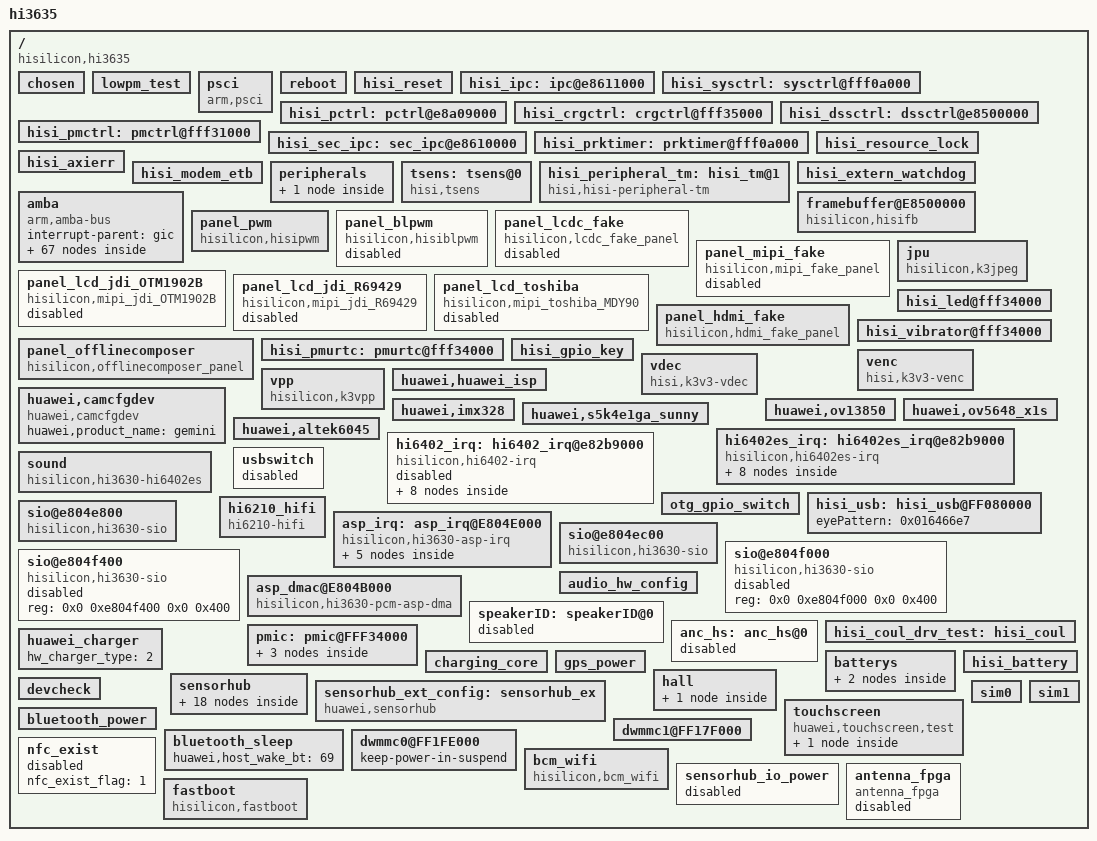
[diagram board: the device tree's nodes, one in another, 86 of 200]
/**
 * Huawei Ltd.
 * PhosphorV660
 */


/include/ "GEMINI_703L_01_pin.dtsi"
/include/ "hisi_3635.dtsi"
///include/ "GEMINI_703L_01_charger.dtsi"
///include/ "GEMINI_703L_01_pmic.dtsi"
///include/ "GEMINI_703L_01_gpio_logic.dtsi"
/include/ "hi3635_mmc.dtsi"
/include/ "hi3635_camera3.dtsi"
/include/ "hi3635_ipc.dtsi"
/include/ "hi3635_ddr.dtsi"
/include/ "hisi_6402es_codec.dtsi"
/include/ "hisi_6402_codec.dtsi"
/include/ "GEMINI_703L_01_hi6402_pin.dtsi"

/include/ "hi3635_usb.dtsi"
/include/ "hi3635_efuse.dtsi"
/include/ "huawei_usbswitch.dtsi"
/include/ "huawei_usb_gpioswitch.dtsi"

/include/ "hi3635_gpu.dtsi"
/include/ "hi3635_noc.dtsi"
/include/ "hi3635_jpeg.dtsi"
/include/ "hi3635_ion.dtsi"
/include/ "hi3635_pmu.dtsi"
/include/ "hi3635_venc.dtsi"
/include/ "hi3635_vdec.dtsi"
/include/ "hi3635_vpp.dtsi"
/include/ "hisi_sim_hotplug.dtsi"
/include/ "huawei_wifi.dtsi"
/include/ "huawei_bluetooth.dtsi"
/include/ "huawei_gps.dtsi"
/include/ "huawei-sensor.dtsi"
/include/ "bq_bci_battery.dtsi"
/include/ "huawei_charger.dtsi"
/include/ "hisi_battery.dtsi"
/include/ "batterys.dtsi"
/include/ "hisi_coul_drv_test.dtsi"
/include/ "GEMINI_703L_01_modem_pin.dtsi"
/*/include/ "huawei_touchscreen.dtsi"*/
/include/ "huawei_hall_inputhub.dtsi"
/include/ "huawei_devdetect.dtsi"
/include/ "huawei_nfc.dtsi"
/include/ "huawei_smartpa.dtsi"
/include/ "huawei_audio.dtsi"
/include/ "huawei_antenna_fpga.dtsi"
/include/ "huawei_bastet.dtsi"
/ {
	#address-cells = <2>;
	#size-cells = <2>;
	model = "hi3635";
	compatible = "hisilicon,hi3635";
	interrupt-parent = <&gic>;

	hisi,boardid = <1 1 0 0 >;
	hisi,boardname = "GEMINI_703L_01";
	hisi,modem_id = <0x3EF50880>;
	hisi,hardware_version="STENGEM703LAPV0001";
	chosen{};

	lowpm_test {
		status = "ok";
	};

	psci {
		compatible      = "arm,psci";
		method          = "smc";
		cpu_suspend     = <0xc4000001>;
		cpu_off         = <0x84000002>;
		cpu_on          = <0xc4000003>;
		system_off      = <0x84000008>;
		system_reset    = <0x84000009>;
	};

	reboot {
		status = "ok";
	};

	hisi_reset {
		status = "ok";
	};

	hisi_ipc: ipc@e8611000 {
		status = "ok";
	};

	hisi_sysctrl: sysctrl@fff0a000 {
		status = "ok";
	};

	hisi_pctrl: pctrl@e8a09000 {
		status = "ok";
	};

	hisi_crgctrl: crgctrl@fff35000 {
		status = "ok";
	};

	hisi_dssctrl: dssctrl@e8500000 {
		status = "ok";
	};

	hisi_pmctrl: pmctrl@fff31000 {
		status = "ok";
	};

	hisi_sec_ipc: sec_ipc@e8610000 {
		status = "ok";
	};

	hisi_prktimer: prktimer@fff0a000 {
		status = "ok";
	};

	hisi_resource_lock {
		status = "ok";
	};

	hisi_axierr {
		status = "ok";
	};

	hisi_modem_etb {
		status = "ok";
	};

	peripherals {
		dma0: dma@fdf30000 {
			status = "ok";
		};
	};

	tsens: tsens@0{
		compatible = "hisi,tsens";
		hisi,sensors = <5>;
		hisi,tsensor_enable_cmd = <0x000E000B>;
		hisi,tsensor_disable_cmd = <0x000E010B>;
		hisi,tsensor_read_thermal_h_cmd = <0x000E0208>;
		hisi,tsensor_read_thermal_l_cmd = <0x000E0209>;
		hisi,tsensor_write_thermal_h_cmd = <0x000E0308>;
		hisi,tsensor_write_thermal_l_cmd = <0x000E0309>;
		hisi,tsensor_read_temperature_cmd = <0x000E020B>;
		hisi,tsensor_int_reback_cmd = <0x080E030B>;
	};

	hisi_peripheral_tm: hisi_tm@1 {
		compatible = "hisi,hisi-peripheral-tm";
		hisi,peripheral_sensors = <13>;

		hisi,detect_system_h_tm_chanel = <3>;
		hisi,detect_system_h_tm_ntc = "hi3630_volt_to_temp_general1";
		hisi,detect_system_h_tm_state = "enable";

		hisi,detect_sim_tm_chanel = <5>;
		hisi,detect_sim_tm_ntc = "hi3630_volt_to_temp_general1";
		hisi,detect_sim_tm_state = "disable";

		hisi,detect_system_l_tm_chanel = <6>;
		hisi,detect_system_l_tm_ntc = "hi3630_volt_to_temp_general1";
		hisi,detect_system_l_tm_state = "enable";

		hisi,detect_flash_led_tm_chanel = <9>;
		hisi,detect_flash_led_tm_ntc = "hi3630_volt_to_temp_general1";
		hisi,detect_flash_led_tm_state = "enable";

		hisi,detect_charger_tm_chanel = <12>;
		hisi,detect_charger_tm_ntc = "hi3630_volt_to_temp_general1";
		hisi,detect_charger_tm_state = "enable";

		hisi,detect_pa_0_tm_chanel = <11>;
		hisi,detect_pa_0_tm_ntc = "hi3630_volt_to_temp_general1";
		hisi,detect_pa_0_tm_state = "enable";

		hisi,detect_pa_1_tm_chanel = <13>;
		hisi,detect_pa_1_tm_ntc = "hi3630_volt_to_temp_general1";
		hisi,detect_pa_1_tm_state = "disable";

		hisi,detect_dcxo0_tm_chanel = <10>;
		hisi,detect_dcxo0_tm_ntc = "hi3630_volt_to_temp_general1";
		hisi,detect_dcxo0_tm_state = "disable";

		hisi,detect_dcxo1_tm_chanel = <12>;
		hisi,detect_dcxo1_tm_ntc = "hi3630_volt_to_temp_general1";
		hisi,detect_dcxo1_tm_state = "disable";

		hisi,detect_board0_tm_chanel = <14>;
		hisi,detect_board0_tm_ntc = "hi3630_volt_to_temp_general1";
		hisi,detect_board0_tm_state = "disable";

		hisi,detect_board1_tm_chanel = <15>;
		hisi,detect_board1_tm_ntc = "hi3630_volt_to_temp_general1";
		hisi,detect_board1_tm_state = "disable";

		hisi,detect_board2_tm_chanel = <16>;
		hisi,detect_board2_tm_ntc = "hi3630_volt_to_temp_general1";
		hisi,detect_board2_tm_state = "disable";

		hisi,detect_board3_tm_chanel = <17>;
		hisi,detect_board3_tm_ntc = "hi3630_volt_to_temp_general1";
		hisi,detect_board3_tm_state = "disable";
	};

	hisi_extern_watchdog {
		status = "ok";
	};

	amba {
		#address-cells = <1>;
		#size-cells = <1>;
		compatible = "arm,amba-bus";
		interrupt-parent = <&gic>;
		ranges;

		rtc@FFF04000 {
			status = "ok";
		};

		wdt0@e8a06000 {
			status = "ok";
		};

		serial0: uart@fdf02000 {
			status = "ok";
		};

		serial1: uart@fdf00000 {
			status = "ok";
		};

		serial2: uart@fdf03000 {
			status = "ok";

		};

		serial3: uart@fdf04000 {
			status = "ok";
		};

		serial4: uart@fdf01000 {
			status = "ok";
		};

		serial5: uart@fdf05000 {
			status = "ok";
		};

		serial6: uart@fff32000 {
			status = "ok";
		};

		hisi_timer4: timer4@e8a00000 {
			status = "ok";
		};

		gpio0: gpio@e8a0b000 {
			status = "ok";
		};

		gpio1: gpio@e8a0c000 {
			status = "ok";
		};

		gpio2: gpio@e8a0d000 {
			status = "ok";
		};

		gpio3: gpio@e8a0e000 {
			status = "ok";
		};

		gpio4: gpio@e8a0f000 {
			status = "ok";
		};

		gpio5: gpio@e8a10000 {
			status = "ok";
		};

		gpio6: gpio@e8a11000 {
			status = "ok";
		};

		gpio7: gpio@e8a12000 {
			status = "ok";
		};

		gpio8: gpio@e8a13000 {
			status = "ok";
		};

		gpio9: gpio@e8a14000 {
			status = "ok";
		};

		gpio10: gpio@e8a15000 {
			status = "ok";
		};

		gpio11: gpio@e8a16000 {
			status = "ok";
		};

		gpio12: gpio@e8a17000 {
			status = "ok";
		};

		gpio13: gpio@e8a18000 {
			status = "ok";
		};

		gpio14: gpio@e8a19000 {
			status = "ok";
		};

		gpio15: gpio@e8a1a000 {
			status = "ok";
		};

		gpio16: gpio@e8a1b000 {
			status = "ok";
		};

		gpio17: gpio@e8a1c000 {
			status = "ok";
		};

		gpio18: gpio@e8a1d000 {
			status = "ok";
		};

		gpio19: gpio@e8a1e000 {
			status = "ok";
		};

		gpio20: gpio@e8a1f000 {
			status = "ok";
		};

		gpio21: gpio@e8a20000 {
			status = "ok";
		};

		gpio22: gpio@fff0b000 {
			status = "ok";
		};

		gpio23: gpio@fff0c000 {
			status = "ok";
		};

		gpio24: gpio@fff0d000 {
			status = "ok";
		};

		gpio25: gpio@fff0e000 {
			status = "ok";
		};

		gpio26: gpio@fff0f000 {
			status = "ok";
		};

		spi0: spi@fdf07000 {
			status = "ok";
			num-cs = <5>;
			pinctrl-names = "default", "idle";
			pinctrl-0 = <&gpio063_pmx_func &gpio065_pmx_func &gpio066_pmx_func &gpio067_pmx_func
					 &gpio068_pmx_func &gpio069_pmx_func &gpio063_cfg_func &gpio064_cfg_func
					 &gpio065_cfg_func &gpio066_cfg_func &gpio068_cfg_func
					 &gpio069_cfg_func>;
			pinctrl-1 = <&gpio063_pmx_idle &gpio065_pmx_idle &gpio066_pmx_idle &gpio067_pmx_idle
					 &gpio068_pmx_idle &gpio069_pmx_idle &gpio063_cfg_idle &gpio064_cfg_idle
					 &gpio065_cfg_idle &gpio066_cfg_idle &gpio068_cfg_idle
					 &gpio069_cfg_idle>;
			#address-cells = <1>;
			#size-cells = <0>;
			//cs-gpios = <&gpio9 7 0>, <&gpio10 0 0>, <&gpio10 1 0>, <&gpio10 2 0>;

			mini_isp: mini_isp@0 {
				compatible = "mini_isp";
				spi-max-frequency = <26000000>;
				reg = <0>;
				pl022,com-mode = <2>;
				pl022,interface = <0>;
				pl022,rx-level-trig = <3>;
				pl022,tx-level-trig = <3>;
				pl022,ctrl-len = <7>;
				pl022,wait-state = <0>;
				pl022,duplex = <0>;
				pl022,slave-tx-disable = <0>;

				mini_isp,reset_gpio = <23>;
				mini_isp,cs_gpio = <66>;
				mini_isp,irq_gpio = <24>;
				mini_isp,dvdd_gpio = <22>;
				mini_isp,vcc_gpio = <210>;
				iopw-supply = <&lsw51>;
				pinctrl-names = "default", "idle";
				pinctrl-0 = <&gpio023_pmx_func &gpio023_cfg_func>;
				pinctrl-1 = <&gpio023_pmx_idle &gpio023_cfg_idle>;
			};

			spi_dev1: spi_dev1@1 {
				compatible = "spi_dev1";
				spi-max-frequency = <100000>;
				reg = <1>;
				pl022,com-mode = <0>;
				pl022,interface = <0>;
				pl022,rx-level-trig = <3>;
				pl022,tx-level-trig = <3>;
				pl022,ctrl-len = <7>;
				pl022,wait-state = <0>;
				pl022,duplex = <0>;
				pl022,slave-tx-disable = <0>;
			};

			spi_dev2: spi_dev2@2 {
				compatible = "spi_dev2";
				spi-max-frequency = <100000>;
				reg = <2>;
				pl022,com-mode = <0>;
				pl022,interface = <0>;
				pl022,rx-level-trig = <3>;
				pl022,tx-level-trig = <3>;
				pl022,ctrl-len = <7>;
				pl022,wait-state = <0>;
				pl022,duplex = <0>;
				pl022,slave-tx-disable = <0>;
			};

			spi_dev3: spi_dev3@3 {
				compatible = "spi_dev3";
				spi-max-frequency = <100000>;
				reg = <3>;
				pl022,com-mode = <0>;
				pl022,interface = <0>;
				pl022,rx-level-trig = <3>;
				pl022,tx-level-trig = <3>;
				pl022,ctrl-len = <7>;
				pl022,wait-state = <0>;
				pl022,duplex = <0>;
				pl022,slave-tx-disable = <0>;
			};
			fpga_spi: fpga_spi@4 {
				compatible = "fpga_spi";
				spi-max-frequency = <0x989680>;
				reg = <4>;
				pl022,com-mode = <2>;
				pl022,interface = <0>;
				pl022,rx-level-trig = <3>;
				pl022,tx-level-trig = <3>;
				pl022,ctrl-len = <7>;
				pl022,wait-state = <0>;
				pl022,duplex = <0>;
				pl022,slave-tx-disable = <0>;
			};
		};

		spi1: spi@fdf08000 {
			status = "ok";
			num-cs = <1>;
			pinctrl-names = "default", "idle";
			pinctrl-0 = <>;
			pinctrl-1 = <>;
			/*
			pinctrl-0 = <&gpio146_pmx_func &gpio147_pmx_func &gpio148_pmx_func &gpio149_pmx_func
				     &gpio146_cfg_func &gpio147_cfg_func &gpio148_cfg_func &gpio149_cfg_func>;
			pinctrl-1 = <&gpio146_pmx_idle &gpio147_pmx_idle &gpio148_pmx_idle &gpio149_pmx_idle
				     &gpio146_cfg_idle &gpio147_cfg_idle &gpio148_cfg_idle &gpio149_cfg_idle>;
			*/
			#address-cells = <1>;
			#size-cells = <0>;
			/*
			spi_dev4: spi_dev4@4 {
				compatible = "spi_dev4";
				spi-max-frequency = <100000>;
				reg = <4>;
				pl022,com-mode = <1>;
				pl022,interface = <0>;
				pl022,rx-level-trig = <3>;
				pl022,tx-level-trig = <3>;
				pl022,ctrl-len = <7>;
				pl022,wait-state = <0>;
				pl022,duplex = <0>;
				pl022,slave-tx-disable = <0>;
			};
			*/
		};

		/* I2C0 ~ I2C4
		Notation for touchscreen and other devices, that is not defined in I2C DTS node:
		if any I2C adapter is disabled, corresponding I2C ID should decreased one by
		one, for example:
			if only I2C0 is disabled, slave devices on I2C1 should get adapter by ID 0
			if only I2C1 is disabled, slave devices on I2C2 should get adapter by ID 1
			and so on........
		*/
		i2c0: i2c@FDF09000 {
			status = "disabled";
			pinctrl-names = "default", "idle";
			pinctrl-0 = <&gpio047_pmx_func &gpio047_cfg_func &gpio048_cfg_func>;
			pinctrl-1 = <&gpio047_pmx_idle &gpio047_cfg_idle &gpio048_cfg_idle>;
			cs-gpios = <&gpio5 7 0>, <&gpio6 0 0>;
		};

		i2c1: i2c@FDF0A000 {
			status = "ok";
			pinctrl-names = "default", "idle";
			pinctrl-0 = <&gpio049_pmx_func &gpio049_cfg_func &gpio050_cfg_func>;
			pinctrl-1 = <&gpio049_pmx_idle &gpio049_cfg_idle &gpio050_cfg_idle>;
			cs-gpios = <&gpio6 1 0>, <&gpio6 2 0>;

			huawei,lm3642@63{
				huawei,flash_current = <0x9>;
				huawei,torch_current = <0x3>;
				status = "ok";
			};

			tps65132_phy: tps65132@3e {
			    compatible = "hisilicon,tps65132_phy";
			    reg = <0x3e>;
			    gpios = <&gpio5 1 0>, <&gpio5 2 0>;
			    status = "ok";
			};
			fairchild_fsa9685: fsa9685@25 {
				 status = "disabled";
			};
			bq2419x_charger:charger@6B {
				status = "disable";
			};
			bq2429x_charger:bq2429x_charger@6B {
				status = "ok";
			};
			max98925_smartpa:smartpa@31{
				status = "ok";
			};
			pn547_nfc:nfc@28 {
				status = "disabled";
				nfc_nxp_name = "libnfc-nxp.conf";
			};
		};

		i2c2: i2c@FDF0B000 {
			status = "ok";
			pinctrl-names = "default", "idle";
			pinctrl-0 = <&gpio051_pmx_func &gpio051_cfg_func &gpio052_cfg_func>;
			pinctrl-1 = <&gpio051_pmx_idle &gpio051_cfg_idle &gpio052_cfg_idle>;
			cs-gpios = <&gpio6 3 0>, <&gpio6 4 0>;

                        cypress_touchscreen@24 {
                               compatible = "cy,cyttsp5_i2c_adapter";
                               reg = <0x24>;
                               cy,adapter_id = "cyttsp5_i2c_adapter";

			       vci_power_type   = <0>; /*0 - gpio control  1 - LDO  2 - boost & gpio*/
                               cypress_vci-supply;
			       vci_gpio_enable  = <&gpio9 1 0>;
			       vci_boost_enable;

			       vddio_power_type   = <1>; /*0 - gpio control  1 - LDO*/
                               cypress_vddio-supply = <&lsw50>;
			       vddio_gpio_enable;
                               
			       cy,i2c_read_length = <100>;
			       pinctrl-names = "default", "idle";
		               pinctrl-0 = <&gpio200_pmx_func  &gpio200_cfg_func>;
                               pinctrl-1 = <&gpio200_pmx_idle  &gpio200_cfg_idle>; 

				hw,mmi_test_limit =
					"0","255","6","0","255","6","0","255","6","0","255","6",                     /*mmi_idac_limit*/
					"79","120","79","120","79","120","75","120",                                 /*mmi_localPWC_limit*/
					"25","4","8", "21","16","10","200","25","5","9", "21","16","10","200",       /*mmi_opens_limit*/
					"25","4","10","21","16","10","200","25","6","10","21","16","10","200",       /*mmi_opens_limit*/
					"-2000","2000","0","-2000","2000","0","-2000","2000","0","-2000","2000","0", /*mmi_mut_rawdata_limit*/
					"-7500","7500","0","-7500","7500","0","-7500","7500","0","-7500","7500","0", /*mmi_self_rawdata_limit*/
					"10","35","255","0","27","10","35","255","0","27",                           /*mmi_selflocalPWC_limit*/
					"10","35","255","0","27","10","35","255","0","30";                           /*mmi_selflocalPWC_limit*/

                               cy,core {
                                       cy,id = "main_ttsp_core";
                                       cy,name = "cyttsp5_core";
                                       cy,irq_gpio = <&gpio25 0 0>;
                                       cy,rst_gpio = <&gpio12 2 0>;
                                       cy,hid_desc_register = <1>;
				       cy,product_name = "Gemini";
				       cy,support_chip_name = "TMA568";
                                       cy,flags = <0>;/*CY_CORE_FLAG_WAKE_ON_GESTURE | CY_CORE_FLAG_RESTORE_PARAMETERS*/
                                       cy,easy_wakeup_gesture = <0>;
                                       cy,upgrade_ttconfig = <0>;
                                       cy,has_touchplus = <1>;
                                       cy,has_holster = <1>;
                                       cy,no_cali_flag = <1>;

			               cy,btn_keys =
                                       <189   /* TS_TOUCHPLUS_KEY0 = KEY_F21, //189 */
				        190   /* TS_TOUCHPLUS_KEY1 = KEY_F22, //190 */
				        191   /* TS_TOUCHPLUS_KEY2 = KEY_F23, //191 */
				        192   /* TS_TOUCHPLUS_KEY3 = KEY_F19, //192 */
				        193>; /* TS_TOUCHPLUS_KEY4 = KEY_F20, //193 */
                                       cy,btn_keys-tag = <0>;
                               cy,mt   {
                                       cy,name = "cyttsp5_mt";
                                       cy,inp_dev_name = "cyttsp5_mt";
                                       cy,flags = <0x00>;/* CY_MT_FLAG_FLIP | CY_MT_FLAG_INV_X | CY_MT_FLAG_INV_Y */
                                       cy,abs =
                                       <0x35   0 1200 0 0           /* ABS_MT_POSITION_X, CY_ABS_MIN_X, CY_ABS_MAX_X, 0, 0 */
                                        0x36   0 1920 0 0           /* ABS_MT_POSITION_Y, CY_ABS_MIN_Y, CY_ABS_MAX_Y, 0, 0 */
                                        0x3a   0 255  0 0           /* ABS_MT_PRESSURE,   CY_ABS_MIN_P, CY_ABS_MAX_P, 0, 0 */
                                        0xffff 0 255  0 0           /* CY_IGNORE_VALUE,   CY_ABS_MIN_W, CY_ABS_MAX_W, 0, 0 */
                                        0x39   0 15   0 0           /* ABS_MT_TRACKING_ID,CY_ABS_MIN_T, CY_ABS_MAX_T, 0, 0 */
                                        0x30   0 255  0 0           /* ABS_MT_TOUCH_MAJOR,0, 255, 0, 0 */
                                        0x31   0 255  0 0           /* ABS_MT_TOUCH_MINOR,0, 255, 0, 0 */
                                        0x34   0xfffffed7 127 0 0>; /* ABS_MT_ORIENTATION,-128, 127, 0, 0 */
                                       };
			       cy,btn {
			              cy,name = "cyttsp5_btn";
				      cy,inp_dev_name = "cyttsp5_btn";
			              };
                               };
                       };   
		};

		i2c3: i2c@FDF0C000 {
			status = "ok";
			pinctrl-names = "default", "idle";
			pinctrl-0 = <&gpio017_pmx_func &gpio018_pmx_func &gpio017_cfg_func &gpio018_cfg_func>;
			pinctrl-1 = <&gpio017_pmx_idle &gpio018_pmx_idle &gpio017_cfg_idle &gpio018_cfg_idle>;
			cs-gpios = <&gpio2 1 0>, <&gpio2 2 0>;

			big-core-mon@40 {
				compatible = "hisilicon,big-core-mon";
				reg = <0x40>;
				status = "ok";
			};
			little-core-mon@41 {
				compatible = "hisilicon,little-core-mon";
				reg = <0x41>;
				status = "ok";
			};
			gpu-mon@42 {
				compatible = "hisilicon,gpu-mon";
				reg = <0x42>;
				status = "ok";
			};
			ddr-mon@44 {
				compatible = "hisilicon,ddr-mon";
				reg = <0x44>;
				status = "ok";
			};
			peri-mon@45 {
				compatible = "hisilicon,peri-mon";
				reg = <0x45>;
				status = "ok";
			};
			battery-mon@46 {
				compatible = "hisilicon,battery-mon";
				reg = <0x46>;
				status = "ok";
			};
		};

		i2c4: i2c@FDF0D000 {
			status = "ok";
			pinctrl-names = "default", "idle";
			pinctrl-0 = <&gpio053_pmx_func &gpio053_cfg_func &gpio054_cfg_func>;
			pinctrl-1 = <&gpio053_pmx_idle &gpio053_cfg_idle &gpio054_cfg_idle>;
			cs-gpios = <&gpio6 5 0>, <&gpio6 6 0>;
		};

		hifidsp {
			compatible = "hisilicon,k3hifidsp";
			reg = <0x0 0xE804E000 0x0 0x120>;
			status = "ok";
		};
	};
	/* end amba */

	/* framebuffer & panel begin */
	framebuffer@E8500000 {
		#address-cells = <2>;
		#size-cells = <2>;
		compatible = "hisilicon,hisifb";
		fpga_flag = <0>;
		fastboot_enable_flag = <0>;
		// dss base, CRGPERI base
		reg = <0 0xE8500000 0 0x80000>, <0 0xFFF35000 0 0x1000>;
		// dss-pdp, dss-sdp, dss-adp, dss-dsi0, dss-dsi1 irq
		interrupts = <0 145 4>, <0 146 4>, <0 147 4>, <0 151 4>, <0 152 4>;
		regulator_dsssubsys-supply = <&dsssubsys>;
		regulator_sdp-supply = <&sdp>;
		regulator_adp-supply = <&adp>;
		clocks = <&aclk_gate_dss>, <&clk_gate_edc0>, <&clk_gate_edc1>, <&clk_gate_ldi0>, <&clk_gate_ldi1>, <&pclk_gate_dss>, <&clk_gate_dphy0>, <&clk_gate_dphy1>;
		clock-names = "aclk_dss", "clk_edc0", "clk_edc1", "clk_ldi0", "clk_ldi1", "pclk_dss", "clk_dphy0", "clk_dphy1";
		status = "ok";
	};

	panel_pwm {
		#address-cells = <2>;
		#size-cells = <2>;
		compatible = "hisilicon,hisipwm";
		reg = <0 0xE8A04000 0 0x1000>;
		clocks = <&clk_gate_pwm>;
		clock-names = "clk_pwm";
		pinctrl-names = "default","idle";
		pinctrl-0 = <&gpio098_pmx_func &gpio098_cfg_func>;
		pinctrl-1 = <&gpio098_pmx_idle &gpio098_cfg_idle>;
		status = "ok";
	};

	panel_blpwm {
		#address-cells = <2>;
		#size-cells = <2>;
		compatible = "hisilicon,hisiblpwm";
		reg = <0 0xE8A05000 0 0x1000>;
		clocks = <&clk_gate_pwm1>;
		clock-names = "clk_pwm1";
		pinctrl-names = "default","idle";
		pinctrl-0 = <&gpio098_pmx_func &gpio098_cfg_func>;
		pinctrl-1 = <&gpio098_pmx_idle &gpio098_cfg_idle>;
		status = "disabled";
	};

	panel_lcdc_fake {
		#address-cells = <2>;
		#size-cells = <2>;
		compatible = "hisilicon,lcdc_fake_panel";
		status = "disabled";
	};

	panel_mipi_fake {
		#address-cells = <2>;
		#size-cells = <2>;
		compatible = "hisilicon,mipi_fake_panel";
		gpios = <&gpio4 3 0>, <&gpio4 5 0>, <&gpio4 6 0>, <&gpio5 1 0>, <&gpio5 2 0>, <&gpio2 3 0>;
		lcdio-vcc-supply = <&lsw50>;
		lcdanalog-vcc-supply = <&ldo17>;
		lcd-vddio-type = <1>;
		status = "disabled";
	};

	panel_lcd_jdi_OTM1902B {
		#address-cells = <2>;
		#size-cells = <2>;
		compatible = "hisilicon,mipi_jdi_OTM1902B";
		gpios = <&gpio4 3 0>, <&gpio4 5 0>, <&gpio4 6 0>, <&gpio5 1 0>, <&gpio5 2 0>;
		lcdio-vcc-supply = <&lsw50>;
		lcdanalog-vcc-supply = <&ldo17>;
		lcd-bl-type = <8>;
		lcd-vddio-type = <1>;
		pinctrl-names = "default", "idle";
		pinctrl-0 = <&gpio036_pmx_func &gpio035_cfg_func &gpio036_cfg_func &gpio037_cfg_func &gpio038_cfg_func &gpio041_cfg_func &gpio042_cfg_func>;
		pinctrl-1 = <&gpio036_pmx_idle &gpio035_cfg_idle &gpio036_cfg_idle &gpio037_cfg_idle &gpio038_cfg_idle &gpio041_cfg_idle &gpio042_cfg_idle>;
		status = "disabled";
	};


	panel_lcd_jdi_R69429 {
		#address-cells = <2>;
		#size-cells = <2>;
		compatible = "hisilicon,mipi_jdi_R69429";
		gpios = <&gpio4 3 0>, <&gpio4 5 0>, <&gpio4 6 0>, <&gpio5 1 0>, <&gpio5 2 0>;		
		lcd-bl-type = <8>;
		lcd-vddio-type = <1>;
		pinctrl-names = "default", "idle";
		pinctrl-0 = <&gpio036_pmx_func &gpio035_cfg_func &gpio036_cfg_func &gpio037_cfg_func &gpio038_cfg_func &gpio041_cfg_func &gpio042_cfg_func>;
		pinctrl-1 = <&gpio036_pmx_idle &gpio035_cfg_idle &gpio036_cfg_idle &gpio037_cfg_idle &gpio038_cfg_idle &gpio041_cfg_idle &gpio042_cfg_idle>;
		status = "disabled";
	};

	panel_lcd_toshiba {
		#address-cells = <2>;
		#size-cells = <2>;
		compatible = "hisilicon,mipi_toshiba_MDY90";
		gpios = <&gpio4 5 0>, <&gpio5 1 0>;
		lcdio-vcc-supply = <&lsw50>;
		lcdanalog-vcc-supply = <&ldo17>;
		pinctrl-names = "default", "idle";
		pinctrl-0 = <&gpio037_cfg_func &gpio041_cfg_func>;
		pinctrl-1 = <&gpio037_cfg_idle &gpio041_cfg_idle>;
		status = "disabled";
	};

	panel_hdmi_fake {
		#address-cells = <2>;
		#size-cells = <2>;
		compatible = "hisilicon,hdmi_fake_panel";
		status = "ok";
	};

	panel_offlinecomposer {
		#address-cells = <2>;
		#size-cells = <2>;
		compatible = "hisilicon,offlinecomposer_panel";
		status = "ok";
	};
	/* framebuffer & panel end */

	jpu{
		compatible = "hisilicon,k3jpeg";
		reg = <0x0 0xE8960000 0x0 0x7FFF>;
		interrupts = <0 140 4>;
		//clock
		clocks = <&clk_gate_jpeg>;
		clock-names = "clk_jpeg";
		//these are for ldo resources
		ldo_jpu-supply = <&jpegip>;
		status = "ok";
	};

	hisi_pmurtc: pmurtc@fff34000 {
		status = "ok";
	};

	hisi_led@fff34000 {
		hi6421,dr3ctrl = "red";
		hi6421,dr4ctrl = "green";
		status = "ok";
	};
	hisi_vibrator@fff34000 {
		/* 1 vibrator working LRA,0 working ERM*/
		hisi,erm_lra = <0>;
		/* 0:2.7V  1:2.8V 2:3.0V 3:3.3V */
		hisi,dr2_test = <2>;
		status = "ok";
	};

	hisi_gpio_key {
		status = "ok";
	};

	venc{
		compatible = "hisi,k3v3-venc";
		reg = <0x0 0xe8900000 0x0 0x10000>;
		interrupts = <0 143 4>;
		clocks = <&clk_gate_venc>;
		clock-names = "clk_venc";
		ldo_venc-supply = <&venc>;
		status = "ok";
	};

	vdec{
		compatible = "hisi,k3v3-vdec";
		reg = <0x0 0xe8910000 0x0 0x10000>;
		interrupts = <0 144 4>;
		clocks = <&clk_gate_vdec>;
		clock-names = "clk_vdec";
		ldo_vdec-supply = <&vdec>;
		status = "ok";
	};

	vpp{
		compatible = "hisilicon,k3vpp";
		reg = <0x0 0xE8968000 0x0 0x1FFF>;
		interrupts = <0 141 4>;
		//clock
		clocks = <&clk_gate_vpp>;
		clock-names = "clk_vpp";
		//these are for ldo resources
		ldo_vpp-supply = <&vppip>;
		status = "ok";
	};

	/* isp & camera sensor & vcm begin */
	/* camera subsystem device */
	huawei,huawei_isp {
		pinctrl-0 = <&gpio031_pmx_func
			     &gpio032_pmx_func
			     &gpio210_pmx_func
			     &gpio022_cfg_func
			     &gpio025_cfg_func
			     &gpio026_cfg_func
			     &gpio027_cfg_func
			     &gpio028_cfg_func
			     &gpio029_cfg_func
			     &gpio030_cfg_func
			     &gpio031_cfg_func
			     &gpio032_cfg_func
			     &gpio033_cfg_func
			     &gpio210_cfg_func
			     >;
		pinctrl-1 = <&gpio031_pmx_idle
			     &gpio032_pmx_idle
			     &gpio210_pmx_idle
			     &gpio022_cfg_idle
			     &gpio025_cfg_idle
			     &gpio026_cfg_idle
			     &gpio027_cfg_idle
			     &gpio028_cfg_idle
			     &gpio029_cfg_idle
			     &gpio030_cfg_idle
			     &gpio031_cfg_idle
			     &gpio032_cfg_idle
			     &gpio033_cfg_idle
			     &gpio210_cfg_idle
			     >;
		status = "ok";
	};

	huawei,camcfgdev {
			compatible = "huawei,camcfgdev";
			huawei,product_name = "gemini";
			status = "ok";
	};

	/* camera sensor device */
	huawei,imx328 {
		status = "ok";
	};

	huawei,ov13850{
		status = "ok";
	};

	huawei,s5k4e1ga_sunny {
		huawei,sensor_chipid = <0xf541>;

		miniisp-supply = <&lsw51>;
		huawei,ldo-names = "avdd", "iopw","miniisp";
		status = "ok";
	};

	huawei,ov5648_x1s {
		huawei,sensor_name = "ov5648";
		miniisp-supply = <&lsw51>;
		huawei,ldo-names = "avdd", "iopw","miniisp";
		status = "ok";
	};

	/* vcm device */

	/* mini isp altek6045&6010 */
	huawei,altek6045 {
		status = "ok";
	};

	/* flash device */
	/* see i2c1: i2c@FDF0A000 -----	huawei,lm3642@63 */

	/* isp & camera sensor & vcm end */

	hi6402es_irq: hi6402es_irq@e82b9000 {
		compatible = "hisilicon,hi6402es-irq";
		hi6402es-irq-supply = <&ldo8>;
		gpios = <&gpio24 6 0>; /* GPIO_198 */
		pinctrl-names = "default", "idle";
		pinctrl-0 = <&gpio016_cfg_func &gpio016_pmx_func
			     &gpio198_cfg_func>;
		pinctrl-1 = <&gpio016_cfg_idle &gpio016_pmx_idle
			     &gpio198_cfg_idle>;
		status = "ok";
		hi6402es_codec: hi6402es_codec@0{
			compatible = "hisilicon,hi6402es-codec";
			hi6402es-codec-supply = <&ldo8>;
			status = "ok";
		};

		hi6402es_mbhc: hi6402es_mbhc@0{
			compatible = "hisilicon,hi6402es-mbhc";
			hisilicon,hs_det = <0>;
			hisilicon,hs_3_pole_min_voltage = <0>;
			hisilicon,hs_3_pole_max_voltage = <8>;
			hisilicon,hs_4_pole_min_voltage = <1350>;
			hisilicon,hs_4_pole_max_voltage = <2565>;
			hisilicon,btn_play_min_voltage = <0>;
			hisilicon,btn_play_max_voltage = <100>;
			hisilicon,btn_volume_up_min_voltage = <130>;
			hisilicon,btn_volume_up_max_voltage = <320>;
			hisilicon,btn_volume_down_min_voltage = <320>;
			hisilicon,btn_volume_down_max_voltage = <700>;
			status = "ok";
		};

		hi6402es_dsp: hi6402es_dsp@0{
			compatible = "hisilicon,hi6402es-dsp";
			status = "ok";
		};

		gpioes28: gpioes@0{
			status = "ok";
		};

		gpioes29: gpioes@1{
			status = "ok";
		};

		gpioes30: gpioes@2{
			status = "ok";
		};

		gpioes31: gpioes@3{
			status = "ok";
		};

		pmxes4: hi6402es_pinctrl {
			status = "ok";
		};
	};

	hi6402_irq: hi6402_irq@e82b9000 {
		compatible = "hisilicon,hi6402-irq";
		hi6402-irq-supply = <&ldo8>;
		hi6402-irq-ldo26-supply = <&ldo26>;
		gpios = <&gpio24 6 0>; /* GPIO_198 */
		pinctrl-names = "default", "idle";
		pinctrl-0 = <&gpio016_cfg_func &gpio016_pmx_func
			     &gpio198_cfg_func>;
		pinctrl-1 = <&gpio016_cfg_idle &gpio016_pmx_idle
			     &gpio198_cfg_idle>;
		status = "disabled";
		hi6402_codec: hi6402_codec@0{
			compatible = "hisilicon,hi6402-codec";
			status = "disabled";
		};

		hi6402_mbhc: hi6402_mbhc@0{
			compatible = "hisilicon,hi6402-mbhc";
			hisilicon,hs_det = <0>;
			hisilicon,hs_3_pole_min_voltage = <0>;
			hisilicon,hs_3_pole_max_voltage = <8>;
			hisilicon,hs_4_pole_min_voltage = <1350>;
			hisilicon,hs_4_pole_max_voltage = <2565>;
			hisilicon,btn_play_min_voltage = <0>;
			hisilicon,btn_play_max_voltage = <100>;
			hisilicon,btn_volume_up_min_voltage = <130>;
			hisilicon,btn_volume_up_max_voltage = <320>;
			hisilicon,btn_volume_down_min_voltage = <320>;
			hisilicon,btn_volume_down_max_voltage = <700>;
			status = "disabled";
		};

		hi6402_dsp: hi6402_dsp@0{
			compatible = "hisilicon,hi6402-dsp";
			status = "disabled";
		};

		gpio28: gpio@0{
			status = "disabled";
		};

		gpio29: gpio@1{
			status = "disabled";
		};

		gpio30: gpio@2{
			status = "disabled";
		};

		gpio31: gpio@3{
			status = "disabled";
		};

		pmx4: hi6402_pinctrl {
			status = "disabled";
		};
	};

	sound {
		compatible = "hisilicon,hi3630-hi6402es";
		status = "ok";
	};

	usbswitch: usbswitch {
		status = "disabled";
	};

	otg_gpio_switch: otg_gpio_switch {
		status = "ok";
	};

	hisi_usb:hisi_usb@FF080000 {
		eyePattern = <0x016466e7>;
	};

	hi6210_hifi {
		compatible = "hi6210-hifi";
		status = "ok";
	};

	asp_irq: asp_irq@E804E000{
		compatible = "hisilicon,hi3630-asp-irq";
		reg = <0x0 0xe804e000 0x0 0xa000>;
		#interrupt-cells = <0x2>;
		asp-irq-supply = <&asp>;
		interrupt-controller;
		interrupts = <0x0 0x88 0x4>;
		interrupt-names = "asp_irq";

		asp_common@0 {
			compatible = "hisilicon,hi3630-asp-common";
		};

		asp_srcup_normal@0 {
			compatible = "hisilicon,hi3630-srcup-normal";
			asp-srcup-normal-supply = <&asp>;
			interrupt-parent = <&asp_irq>;
			interrupts = <0x1 0x0>;
			interrupt-names = "asp_srcup_normal";
		};

		asp_srcup_dsp@0 {
			compatible = "hisilicon,hi3630-srcup-dsp";
		};

		asp_srcdown@0 {
			compatible = "hisilicon,hi3630-srcdown";
			interrupt-parent = <&asp_irq>;
		};

		asp_hdmi@0 {
			compatible = "hisilicon,hi3630-pcm-hdmi";
			interrupt-parent = <&asp_irq>;
			interrupts = <0x0 0x0>;
			interrupt-names = "asp_irq_hdmi";
		};
	};

	sio@e804e800 {
		compatible = "hisilicon,hi3630-sio";
		reg = <0x0 0xe804e800 0x0 0x400>;
		sio-audio-supply = <&asp>;
		pinctrl-names = "default", "idle";
		pinctrl-0 = <&gpio183_pmx_func
				    &gpio184_pmx_func
				    &gpio185_pmx_func
				    &gpio186_pmx_func
				    &gpio183_cfg_func
				    &gpio184_cfg_func
				    &gpio185_cfg_func
				     &gpio186_cfg_func>;
		pinctrl-1 = <&gpio183_pmx_idle
				    &gpio184_pmx_idle
				    &gpio185_pmx_idle
				    &gpio186_pmx_idle
				    &gpio183_cfg_idle
				    &gpio184_cfg_idle
				    &gpio185_cfg_idle
				    &gpio186_cfg_idle>;
		status = "ok";
	};

	sio@e804ec00 {
		compatible = "hisilicon,hi3630-sio";
		reg = <0x0 0xe804ec00 0x0 0x400>;
		sio-voice-supply = <&asp>;
		pinctrl-names = "default", "idle";
		pinctrl-0 = <&gpio043_pmx_func
				     &gpio044_pmx_func
				     &gpio045_pmx_func
				     &gpio046_pmx_func
				     &gpio043_cfg_func
				     &gpio044_cfg_func
				     &gpio045_cfg_func
				     &gpio046_cfg_func>;
			pinctrl-1 = <&gpio043_pmx_idle
				     &gpio044_pmx_idle
				     &gpio045_pmx_idle
				     &gpio046_pmx_idle
				     &gpio043_cfg_idle
				     &gpio044_cfg_idle
				     &gpio045_cfg_idle
				     &gpio046_cfg_idle>;
		status = "ok";
	};

	sio@e804f000 {
		compatible = "hisilicon,hi3630-sio";
		reg = <0x0 0xe804f000 0x0 0x400>;
		status = "disabled";
	};

	sio@e804f400 {
		compatible = "hisilicon,hi3630-sio";
		reg = <0x0 0xe804f400 0x0 0x400>;
		status = "disabled";
	};

	asp_dmac@E804B000 {
		compatible = "hisilicon,hi3630-pcm-asp-dma";
		reg = <0x0 0xe804b000 0x0 0x1000>;
		asp-dmac-supply = <&asp>;
		interrupts = <0 212 4>;
		interrupt-names = "asp_dma_irq";
	};

	audio_hw_config {
		product_name = "GEMINI";
		cust_name = "audio_custom";
		spk_pa_name = "max98925";
		soc_name = "hi363x";
		codec_name = "hi6402";
		codec_dsp_algo = "maxim|mad";
		modem_sio_master = "true";
		status = "ok";
	};

	speakerID: speakerID@0 {
		status = "disabled";
	};

	anc_hs: anc_hs@0{
		status = "disabled";
	};

	hisi_coul_drv_test:hisi_coul {
		status = "ok";
	};
	pmic: pmic@FFF34000 {
		ocpirq {
			hisi-ocp-mask = <0x00 0x00 0x31 0x00 0x00 0x00 0x00>;/*0:OPEN Regulator OCP;1:CLOSE Regulator OCP;*/
			ocp_debug_enable = <0>;
		};
		coul: coul@1 {
		};
		bq_bci_battery:battery {
			compatible = "huawei,bq_bci_battery";
			status = "ok";
		};
	};
	huawei_charger:huawei_charger {
		hw_charger_type = <2>;
		status = "ok";
	};
	charging_core:charging_core {
		iin_ac = <2000>;
		ichg_ac = <2000>;
		ichrg_pre_limit = <384>;
		iterm = <150>;
		vdpm_para =
			"-32767", "90", "4440", "0",
			"90", "32767", "4600", "0";
		status = "ok";
	};
	batterys:batterys {
		coslightguangyu_4850_22k:coslightguangyu_4850_22k {
			temp_para =
				"-32767","0","-1","0","4352","0",
				"0","10","-1","1455","4352","3",
				"10","45","-1","-1","4352","3",
				"45","32767","-1","0","4352","0";
			vbat_para =
				"-32767","3400","-1","1455","0",
				"3400","32767","-1","-1","0";
		};
		scudsony_4850_110k:scudsony_4850_110k {
			temp_para =
				"-32767","0","-1","0","4352","0",
				"0","10","-1","1455","4352","3",
				"10","45","-1","-1","4352","3",
				"45","32767","-1","0","4352","0";
			vbat_para =
				"-32767","3400","-1","1455","0",
				"3400","32767","-1","-1","0";
		};
	};
	hisi_battery:hisi_battery {
		batt_name = <&coslightguangyu_4850_22k &scudsony_4850_110k>;
		status = "ok";
	};
	gps_power:gps_power{
		huawei,gps_hostwake = <&gpio0 0 0>;
		status = "ok";
		broadcom_config,ic_type= "bcm4752";
		broadcom_config,tty_port="ttyAMA3";
		broadcom_config,product="hi3635";
		broadcom_config,ref_clk_sel_enable="no";
	};


	hall {
		status = "ok";
		huawei,hall_0{
			huawei,default-state = "on";
		};
	};

	sensorhub{
		acc_sensor:gsensor{
			acc1{
				file_id=<0x0a>;
				axis_map_x=<0>;
				axis_map_y=<1>;
				axis_map_z=<2>;
				negate_x=<0>;
				negate_y=<0>;
				negate_z=<0>;
				offset_x=<0>;
				offset_y=<0>;
				offset_z=<0>;
				gpio_int1=<&gpio26 0 0>;
				gpio_int2=<&gpio26 3 0>;
				status = "ok";
			};
			acc2{
				compatible="huawei,st-lsm6ds3";
				bus_number=<0>;
				reg=<0x6a>;
				chip_id_register=<0x0f>;
				chip_id_value=<0x69>;
				file_id=<0x11>;
				sensor_list_info_id=<0>;
				sensor_type="acc";
				sensor-vdd-supply = <&ldo24>;
				axis_map_x=<1>;
				axis_map_y=<0>;
				axis_map_z=<2>;
				negate_x=<0>;
				negate_y=<1>;
				negate_z=<0>;
				offset_x=<0>;
				offset_y=<0>;
				offset_z=<0>;
				poll_interval=<10>;
				gpio_int1=<&gpio26 0 0>;
				gpio_int2=<&gpio26 3 0>;
				status = "ok";
			};
			acc3{
				compatible="huawei,bosch-bmi160";
				bus_number=<0>;
				reg=<0x68>;
				chip_id_register=<0x0>;
				chip_id_value=<0xd1>;
				file_id=<0x14>;
				sensor_list_info_id=<0>;
				sensor_type="acc";
				sensor-vdd-supply = <&ldo24>;
				axis_map_x=<0>;
				axis_map_y=<1>;
				axis_map_z=<2>;
				negate_x=<0>;
				negate_y=<0>;
				negate_z=<0>;
				offset_x=<0>;
				offset_y=<0>;
				offset_z=<0>;
				poll_interval=<10>;
				gpio_int1=<&gpio26 0 0>;
				gpio_int2=<&gpio26 3 0>;
				status = "ok";
			};
		};


		gyro_sensor:gyroscope{
			gyro1{
				file_id=<0x0b>;
				axis_map_x=<0>;
				axis_map_y=<1>;
				axis_map_z=<2>;
				negate_x=<0>;
				negate_y=<0>;
				negate_z=<0>;
				gpio_int1=<&gpio26 0 0>;
				gpio_int2=<&gpio26 3 0>;
				status = "ok";
			};
			gyro2{
				compatible="huawei,st-lsm6ds3";
				bus_number=<0>;
				reg=<0x6a>;
				chip_id_register=<0x0f>;
				chip_id_value=<0x69>;
				file_id=<0x11>;
				sensor_list_info_id=<5>;
				sensor_type="gyro";
				sensor-vdd-supply = <&ldo24>;
				axis_map_x=<1>;
				axis_map_y=<0>;
				axis_map_z=<2>;
				negate_x=<0>;
				negate_y=<1>;
				negate_z=<0>;
				poll_interval=<10>;
				gpio_int1=<&gpio26 0 0>;
				gpio_int2=<&gpio26 3 0>;
				status = "ok";
			};
			gyro3{
				compatible="huawei,bosch-bmi160";
				bus_number=<0>;
				reg=<0x68>;
				chip_id_register=<0x0>;
				chip_id_value=<0xd1>;
				file_id=<0x14>;
				sensor_list_info_id=<5>;
				sensor_type="gyro";
				sensor-vdd-supply = <&ldo24>;
				axis_map_x=<0>;
				axis_map_y=<1>;
				axis_map_z=<2>;
				negate_x=<0>;
				negate_y=<0>;
				negate_z=<0>;
				poll_interval=<10>;
				gpio_int1=<&gpio26 0 0>;
				gpio_int2=<&gpio26 3 0>;
				status = "ok";
			};
		};

		mag_sensor:compass{
			mag1{
				reg=<0x0c>;
				file_id=<4>;
				axis_map_x=<0>;
				axis_map_y=<1>;
				axis_map_z=<2>;
				negate_x=<1>;
				negate_y=<0>;
				negate_z=<1>;
				softiron_parameter = <3 76 15 111 220 106 0 139 213 55 186 230 47 179 5 179 3 93 152 197 193 247 93 186 12 5 97>;
				status = "ok";
			};
		};

		als_sensor:light{
			als1{
				file_id=<9>;
				GA1=<3500>;
				GA2=<3700>;
				GA3=<3800>;
				COE_B = <1860>;
				COE_C = <75>;
				COE_D = <1290>;
				status = "ok";
			};
			als2{
				compatible="huawei,mura-lt_1pa01";
				bus_number=<0>;
				reg=<0x44>;
				chip_id_register=<0x0>;
				chip_id_value=<0xc8 0xc9 0xca 0xcf>;
				file_id=<0xF>;
				sensor_list_info_id=<0xb>;
				sensor_type="als";
				sensor-vdd-supply = <&ldo24>;
				poll_interval=<500>;   //?·?31a???ˉ×?D?ê±??????
				threshold_value=<1>;
				GA1=<4166>; //2￡á§í?1a?ê ￡?3??1a?′
				GA2=<3900>; //2￡á§í?1a?ê
				GA3=<4500>; //2￡á§í?1a?ê
				tp_color =<0>;
				again=<0x15>; //′?ì??¤1asensor?D?·?3oìía1a213￥?μêy
				gpio_int1=<&gpio25 6 0>;
				atime=<3>; //′?ì??¤1asensor?Dé?±¨?·?31aêy?μμ?×a???μêy,oí?áμ?2??êóD1?
				init_time = <150>;   //?·?31a3?ê??ˉê±??
				status = "ok";
			};
			als3{
				compatible="huawei,rohm_rpr0521";
				bus_number=<0>;
				reg=<0x38>;
				chip_id_register=<0x92>;
				chip_id_value=<0xE0>;
				file_id=<0x10>;
				sensor_list_info_id=<0xd>;
				sensor_type="als";
				sensor-vdd-supply = <&ldo24>;
				poll_interval=<500>;   //?·?31a???ˉ×?D?ê±??????
				threshold_value=<1>;
				GA1=<0>; //2￡á§í?1a?ê ￡?3??1a?′
				GA2=<0>; //2￡á§í?1a?ê
				GA3=<0>; //2￡á§í?1a?ê
				tp_color =<0>;
				again=<5>; // ROHM ALS gain value in 42h register
				gpio_int1=<&gpio25 6 0>;
				atime=<0>;
				init_time = <150>;   //?·?31a3?ê??ˉê±??
				als_extend_data = <7768 4388 2627 1971 5066 2315 1106 687 1032 1605 1904 2864>; //ROHM ALS coefficient
				status = "ok";
			};
		};
		//new tp
		ps_sensor:proximity{
			ps1{
				file_id=<9>;
				pwave_value=<30>;
				pwindows_value=<110>;
				threshold_value=<50>;
				poll_interval = <150>;
				status = "ok";
			};
			ps2{
				compatible="huawei,mura-lt_1pa01";
				bus_number=<0>;
				reg=<0x44>;
				chip_id_register=<0x0>;
				chip_id_value=<0xc8 0xc9 0xca 0xcf>;
				file_id=<0xF>;
				sensor_list_info_id=<0xc>;
				sensor_type="ps";
				sensor-vdd-supply = <&ldo24>;
				tp_color =<0>;
				min_proximity_value=<200>;
				pwindows_value=<120>;
				pwave_value=<5>;
				threshold_value=<25>;
				ps_pulse_count=<5>;
				persistent=<0x33>;
				rdata_under_sun=<5500>;
				gpio_int1=<&gpio25 6 0>;
				ptime=<0>; //′?ì??¤1asensor?D?ó?ü1a213￥
				p_on = <0>;   //?ˉ???ú??ê?·?Dèòa1?±??§??
				poll_interval = <300>;
				init_time = <50>;
				status = "ok";
			};
			ps3{
				compatible="huawei,rohm_rpr0521";
				bus_number=<0>;
				reg=<0x38>;
				chip_id_register=<0x92>;
				chip_id_value=<0xE0>;
				file_id=<0x10>;
				sensor_list_info_id=<0xe>;
				sensor_type="ps";
				sensor-vdd-supply = <&ldo24>;
				tp_color =<0>;
				min_proximity_value=<750>;
				pwindows_value=<38>;
				pwave_value=<12>;
				threshold_value=<10>;
				ps_pulse_count=<0>; // ROHM PS_PUSLE in 41h register
				persistent=<1>; // ROHM PS_CONTROL in 43h register
				rdata_under_sun=<5500>;
				gpio_int1=<&gpio25 6 0>;
				ptime=<0xFF>;
				p_on = <2>;   // ROHM LED_CURRENT in 42h register
				poll_interval = <300>;
				init_time = <50>;
				status = "ok";
			};
		};
	};

	sensorhub_ext_config:sensorhub_ex{
		compatible = "huawei,sensorhub";
		akm_need_current = "no";
		invensense_exist = "no";
		isensor_version = "yes";
		adapt_file_id = <0x07 0x08 0x0c 0x0d>;
	};

	/*
		device check : the 0 means that it don't need to check;
			the 1 means that it check at board check and running test;
			the 2 means that it check at running test
	*/
	devcheck: devcheck {
		touch_panel = <2>;
		compass = <1>;
		g_sensor = <1>;
		gyroscope = <1>;
		nfc = <0>;
		dc_dc = <1>;
		tps = <1>;
		l_sensor = <2>;
		charge = <1>;
		usb_switch = <0>;
		wifi = <1>;
		bt = <1>;
		gps = <1>;
		gpu = <1>;
		status = "ok";
	};

	touchscreen {
             compatible = "huawei,touchscreen,test";
	     bus_type = "i2c";
             bus_id = <1>;
	     product = "hi6210_X1S";
	     support_chip_name = "cypress-hid";
             protocol_hid = <1>;
	     has_virtualkey = <0>;
	     cypress_hid: touchscreen@24 {
	                /*compatible = "cypress-hid";*/
			slave_address = <0x24>;
			vci_gpio_type = <1>;
			vci_enable = <&gpio9 1 0>;
            		vci_regulator_type = <0>;
			cypress-vci-supply;
            		vci_boost_type = <0>;
			vci_boost_enable;
            		vddio_gpio_type = <0>;
			vddio_enable;
			vddio_regulator_type = <1>;
			cypress-vddio-supply  = <&lsw50>;
			reset_gpio = <&gpio12 2 0>;
			attn_gpio = <&gpio25 0 0>;
			irq_config = <3>;
			algo_id = <1>;
			pinctrl-names = "default", "idle";
			product_lcd_x = <1200>;
			product_lcd_y = <1920>;
		};
	};
	bluetooth_power:bluetooth_power{
		huawei,vio_en = <20>;
		huawei,bt_en = <68>;
		status = "ok";
        };

	bluetooth_sleep:bluetooth_sleep{
		huawei,host_wake_bt = <69>;
		status = "ok";
        };

	dwmmc0@FF1FE000 {
		keep-power-in-suspend;
	};

	dwmmc1@FF17F000 {
		cd-vol = <0>;
                cd-gpio = <&gpio12 0 0>;
	};

	/*Begin: DTS2014111501547 modified by j00165480 for tablet wifi, 20141115*/
	bcm_wifi {
		compatible = "hisilicon,bcm_wifi";
		clocks = <&clk_pmu32kb>;
		clock-names = "apb_pclk";
		wlan-on,gpio-enable= <&gpio5 0 0>;
		wlan-irq,gpio-irq = <&gpio26 4 0>;
		wlan_enable,gpio_vio = <&gpio2 4 0>;
		wifi_nvram_name = "/vendor/firmware/nvram4334_hw_gemini_l.txt";
		wifi_fw_name = "/vendor/firmware/fw_bcm4334_hw_2ant.bin";
		wifi_fw_ap_name = "/vendor/firmware/fw_bcm4334_apsta_hw_2ant.bin";
		wifi_fw_test_name = "/vendor/firmware/fw_bcm4334_test_2ant.bin";
		status = "ok";
		product="tablet";
		ic_type="bcm4334";
		freq_table_t = <8000  604800  0
			16000 806400  0
			30000 1305600 667000000>;
	};
	/*End: DTS2014111501547 modified by j00165480 for tablet wifi, 20141115*/
	sensorhub_io_power{
		status="disabled";
	};
	nfc_exist {
		nfc_exist_flag = "1";
		status = "disabled";
	};
	antenna_fpga{
		compatible = "antenna_fpga";
		antenna_fpga,gpio-reset= <&gpio0 2 0>;
		antenna_fpga,gpio-cdone = <&gpio4 1 0>;
		antenna_fpga,gpio-cs = <&gpio8 3 0>;
		antenna_fpga,gpio-exception = <&gpio24 1 0>;
		antenna_fpga,pre-image-filename = "GRACE-TUGL-V1.bin";
		antenna_fpga,vccio0 = "LSW50";
		status = "disabled";
	};

	fastboot {
		compatible = "hisilicon,fastboot";
		gpio-keyup = <203>;
		gpio-keydown = <204>;
	};

	sim0 {
		gpios = <&gpio25 1 0>;
		status = "ok";
		set_gpio="disabled";
		detect_pin_direction="open";
		card_tray = <0>;
		hpd_trigger = <0x11>;
		debounce_settings = <0x27>;
	};

	sim1 {
		gpios = <&gpio25 5 0>;
		status = "ok";
		set_gpio="disabled";
		detect_pin_direction="open";
		card_tray = <0>;
		hpd_trigger = <0x11>;
		debounce_settings = <0x27>;
	};
};
